# Secure_IoT register map
Vendor: Mindgrove Technologies Private Limited; Series: Mindgrove Silicon; File version: 1.0.0
CPU: VAJRA r1p9, little endian, MPU, FPU, double-precision FPU, I-cache, D-cache, 7 interrupt priority bits
Registers are 32-bit, read-write, reset 0x0 unless marked. A register's access mark holds for its fields unless they carry their own. Offsets are from the block's base; [hi:lo] are bit positions; {n}, {i} and the like mark numbered series.

## I2C0 — I2C communication peripheral
Base 0x00044000
Same registers: I2C1 0x00044100
0x00 S2 8-bit — Prescalar register
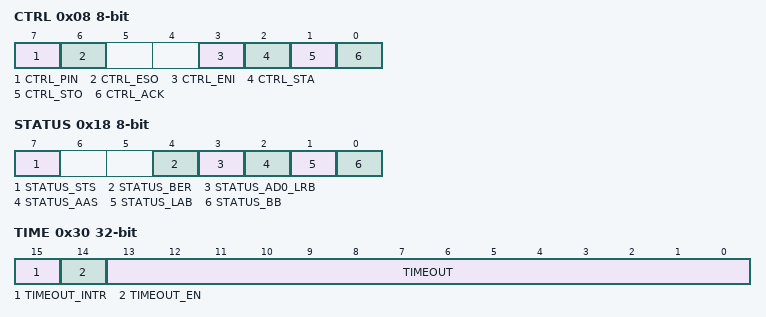
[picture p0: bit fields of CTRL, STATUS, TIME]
0x08 CTRL 8-bit — Control register
  [7] CTRL_PIN — Used as a software reset. If pin is 1 all status bits are reset.Used as transmission complete status in polled applications
  [6] CTRL_ESO — Enable Serial Output. ESO = 0 - Registers can be initialized. ESO = 1 - I2C Serial Transmission
  [3] CTRL_ENI — Enables the external interrupt output
  [2] CTRL_STA — Sends the start bit
  [1] CTRL_STO — Sends the stop bit
  [0] CTRL_ACK — Sends the acknoledge bit
0x10 S0 8-bit — Data Transmission register
0x18 STATUS 8-bit
  [7] STATUS_STS — Read the PIN bit of control register
  [4] STATUS_BER — Bus Error - Set to 1 when there is a misplaced START, STOP bit
  [3] STATUS_AD0_LRB — LRB - holds the last received bit through I2C bus. AD0 - Generall Call bit used for broadcast. Valid only while PIN=0
  [2] STATUS_AAS — Addressed as slave - Used in Slave Receiver mode
  [1] STATUS_LAB — Lost Arbitration bit - Used in Multiple Master systems only to denote that the master lost the arbitration
  [0] STATUS_BB — Bus Busy bit - Indicates that the bus is busy(0 = busy). Also used in multi master systems only. 0 = busy
0x20 S01 — I2C Own Address Slave Register
0x28 S3 — Interrupt vector register
0x30 TIME — I2C timeout calculation and interrupt register
  [15] TIMEOUT_INTR — Interrupt output for transmission timeout
  [14] TIMEOUT_EN — Enable the transmission timeout calculation and interrupt generation
  [13:0] TIMEOUT — The transmission timeout value
0x38 SCL — Clock period register

## WDT0 — Watchdog Timer
Base 0x00040400
0x00 WDT_CYCLES — The number of cycles to count down for reset generation
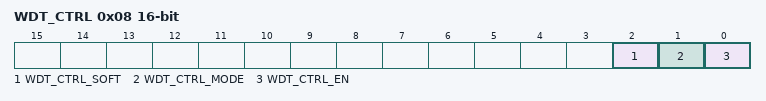
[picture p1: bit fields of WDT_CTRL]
0x08 WDT_CTRL 16-bit — Control register
  [2] WDT_CTRL_SOFT — Software reset
  [1] WDT_CTRL_MODE — Mode of watchdog timer. 0 - Interrupt, 1 - Reset
  [0] WDT_CTRL_EN — Enable the watchdog timer
0x10 WDT_RESET_CYCLES 16-bit — The number of cycles for which the interrupt needs to be held
0x18 WDT_ACTIVE — Update the internal WD counter with the WD_CYCLES register

## PINMUX0 — Pinmux which selects between GPIO and PWM.
Base 0x00040300
{0x0+4i} MUX{i} (i=0..7) — Select between GPIO{i} and PWM{i}. 0 - GPIO, 1 - PWM

## GPIO — General purpose IO. 32 GPIOs are available
Base 0x00040200
0x00 GPIO_DIRECTION — Select the direction of the GPIOs. Each bit position corresponds to the respective GPIO pin. 0 - Output, 1 - Input
0x08 GPIO_DATA — Contains the data to be sent out if the GPIO pin is configured as output and the data recieved when configured as input. Each bit position corresponds to the respective GPIO pin.
0x10 GPIO_SET — To set the respective GPIO pins
0x18 GPIO_CLEAR — To clear the respective GPIO pins
0x20 GPIO_TOGGLE — To invert the respective GPIO pins
0x30 GPIO_INTR — To enable the interrupt of respective GPIO pins

## AES — AES algorithm accelerator
Base 0x04000000
0x00 AES_INPUT 64-bit wo (reset mask 0xFFFFFFFF) — Input text register. Input is given 64 bits at a time.
0x20 AES_KEY 64-bit wo (reset mask 0xFFFFFFFF) — Key data register. Key is given 64 bits at a time and needs to be written depending on the keylen select
0x40 AES_OUTPUT 64-bit ro (reset mask 0xFFFFFFFF) — Output register. Output is read 64 bits at a time.
0x50 AES_IV 64-bit wo (reset mask 0xFFFFFFFF) — Initialization vector register. IV is given 64 bits at a time.
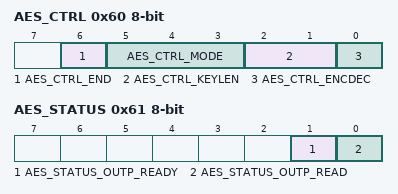
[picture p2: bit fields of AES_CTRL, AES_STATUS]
0x60 AES_CTRL 8-bit — Control register
  [6] AES_CTRL_END — To specify end of message
  [5:3] AES_CTRL_MODE — 0-ECB, 1-CBC, 2-CFB, 3-OFB, 4-CTR
  [2:1] AES_CTRL_KEYLEN — To select the lenght of key. 0 - 128 bits, 1 - 192 bits, 2 - 256 bits
  [0] AES_CTRL_ENCDEC — 0 - Encrypt, 1 - Decrypt
0x61 AES_STATUS 8-bit — To check the status.
  [1] AES_STATUS_OUTP_READY — Becomes 1 when the accelerator has computed the output. Becomes 0 once new input is given.
  [0] AES_STATUS_OUTP_READ — Once the output is ready and read, this bit becomes 0.
0x70 AES_NEXT_BLK 64-bit wo (reset mask 0xFFFFFFFF) — The input data of the next block of the same message
